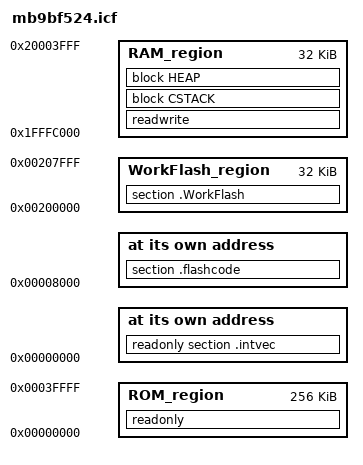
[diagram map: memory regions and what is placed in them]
/*###ICF### Section handled by ICF editor, don't touch! ****/
/*-Editor annotation file-*/
/* IcfEditorFile="$TOOLKIT_DIR$\config\ide\IcfEditor\cortex_v1_0.xml" */
/*-Specials-*/
define symbol __ICFEDIT_intvec_start__ = 0x0;
/*-Memory Regions-*/
define symbol __ICFEDIT_region_ROM_start__ = 0x0;
define symbol __ICFEDIT_region_ROM_end__   = 0x0003FFFF;
define symbol __ICFEDIT_region_RAM_start__ = 0x1FFFC000;
define symbol __ICFEDIT_region_RAM_end__   = 0x20003FFF;
/*-Sizes-*/
define symbol __ICFEDIT_size_cstack__ = 0x400;
define symbol __ICFEDIT_size_heap__   = 0x800;
/**** End of ICF editor section. ###ICF###*/

define symbol WorkFlash_region_start = 0x00200000;
define symbol WorkFlash_region_end   = 0x00207FFF;

define memory mem with size = 4G;
define region ROM_region   = mem:[from __ICFEDIT_region_ROM_start__   to __ICFEDIT_region_ROM_end__];
define region RAM_region   = mem:[from __ICFEDIT_region_RAM_start__   to __ICFEDIT_region_RAM_end__];
define region WorkFlash_region = mem:[from   WorkFlash_region_start       to   WorkFlash_region_end    ];

define block CSTACK    with alignment = 8, size = __ICFEDIT_size_cstack__   { };
define block HEAP      with alignment = 8, size = __ICFEDIT_size_heap__     { };

initialize by copy { readwrite };
do not initialize  { section .noinit };

place at address mem:__ICFEDIT_intvec_start__ { readonly section .intvec };

place in WorkFlash_region { section .WorkFlash };

place in ROM_region   { readonly };
place in RAM_region   { readwrite,
                        block CSTACK, block HEAP };
place at address mem:0x00008000 { section .flashcode };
